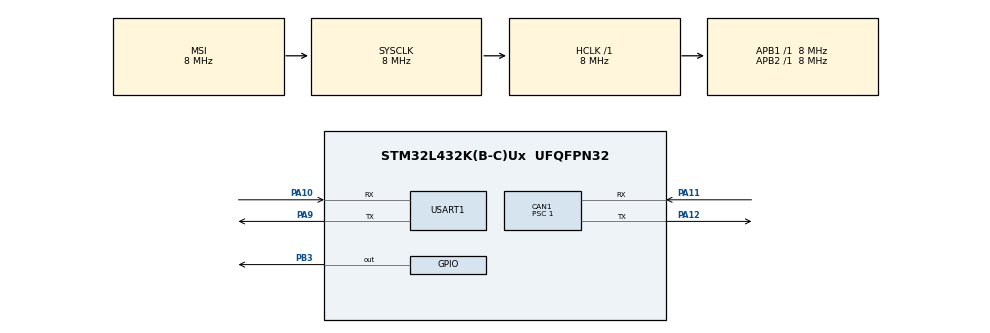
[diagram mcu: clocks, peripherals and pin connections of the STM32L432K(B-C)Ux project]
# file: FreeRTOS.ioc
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CAN1.BS1=CAN_BS1_5TQ
CAN1.BS2=CAN_BS2_2TQ
CAN1.CalculateBaudRate=1000000
CAN1.CalculateTimeBit=1000
CAN1.CalculateTimeQuantum=125.0
CAN1.Prescaler=1
FREERTOS.Tasks01=defaultTask,0,128,canopen_task,Default,NULL,Dynamic,NULL,NULL;myTask02,0,128,blink_task,Default,NULL,Dynamic,NULL,NULL
FREERTOS.configUSE_NEWLIB_REENTRANT=1
Mcu.Family=STM32L4
Mcu.Name=STM32L432K(B-C)Ux
Mcu.Package=UFQFPN32
NVIC.CAN1_RX0_IRQn=true\:5\:0\:false\:false\:true\:true\:true\:true\:true
NVIC.CAN1_RX1_IRQn=true\:5\:0\:false\:false\:true\:true\:true\:true\:true
NVIC.CAN1_TX_IRQn=true\:5\:0\:false\:false\:true\:true\:true\:true\:true
NVIC.PriorityGroup=NVIC_PRIORITYGROUP_4
NVIC.TIM1_UP_TIM16_IRQn=true\:15\:0\:false\:false\:true\:false\:false\:true\:true
NVIC.TIM7_IRQn=true\:5\:0\:false\:false\:true\:true\:true\:true\:true
NVIC.TimeBase=TIM1_UP_TIM16_IRQn
NVIC.TimeBaseIP=TIM1
NVIC.USART1_IRQn=true\:5\:0\:false\:false\:true\:true\:true\:true\:true
PA10.Mode=Asynchronous
PA10.Signal=USART1_RX
PA11.Mode=CAN_Activate
PA11.Signal=CAN1_RX
PA12.Mode=CAN_Activate
PA12.Signal=CAN1_TX
PA13\ (JTMS-SWDIO).Mode=Serial_Wire
PA13\ (JTMS-SWDIO).Signal=SYS_JTMS-SWDIO
PA14\ (JTCK-SWCLK).Mode=Serial_Wire
PA14\ (JTCK-SWCLK).Signal=SYS_JTCK-SWCLK
PA9.Mode=Asynchronous
PA9.Signal=USART1_TX
PB3\ (JTDO-TRACESWO).Signal=GPIO_Output
ProjectManager.HeapSize=0x200
ProjectManager.StackSize=0x400
ProjectManager.TargetToolchain=STM32CubeIDE
RCC.ADCFreq_Value=32000000
RCC.AHBFreq_Value=8000000
RCC.APB1Freq_Value=8000000
RCC.APB1TimFreq_Value=8000000
RCC.APB2Freq_Value=8000000
RCC.APB2TimFreq_Value=8000000
RCC.CortexFreq_Value=8000000
RCC.HCLKFreq_Value=8000000
RCC.HSE_VALUE=8000000
RCC.HSI48_VALUE=48000000
RCC.HSI_VALUE=16000000
RCC.LSE_VALUE=32768
RCC.MSIClockRange=RCC_MSIRANGE_7
RCC.MSI_VALUE=8000000
RCC.SYSCLKFreq_VALUE=8000000
RCC.USBFreq_Value=32000000
RCC.VCOOutputFreq_Value=64000000
TIM7.Period=1000
TIM7.Prescaler=63
USART1.VirtualMode-Asynchronous=VM_ASYNC
VP_FREERTOS_VS_CMSIS_V1.Mode=CMSIS_V1
VP_SYS_VS_tim1.Mode=TIM1
VP_TIM7_VS_ClockSourceINT.Mode=Enable_Timer
board=custom

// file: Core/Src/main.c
/* USER CODE BEGIN Header */
/**
  ******************************************************************************
  * @file           : main.c
  * @brief          : Main program body
  ******************************************************************************
  * @attention
  *
  * Copyright (c) 2024 STMicroelectronics.
  * All rights reserved.
  *
  * This software is licensed under terms that can be found in the LICENSE file
  * in the root directory of this software component.
  * If no LICENSE file comes with this software, it is provided AS-IS.
  *
  ******************************************************************************
  */
/* USER CODE END Header */
#include "main.h"
#include "cmsis_os.h"

/* USER CODE BEGIN Includes */
#include "CO_app_STM32.h"
/* USER CODE END Includes */

CAN_HandleTypeDef hcan1;

TIM_HandleTypeDef htim7;

UART_HandleTypeDef huart1;

osThreadId defaultTaskHandle;
osThreadId myTask02Handle;
/* USER CODE BEGIN PV */
uint8_t data[3] = "OK!";
/* USER CODE END PV */

void SystemClock_Config(void);
static void MX_GPIO_Init(void);
static void MX_CAN1_Init(void);
static void MX_TIM7_Init(void);
static void MX_USART1_UART_Init(void);
void canopen_task(void const * argument);
void blink_task(void const * argument);

int main(void)
{

  /* MCU Configuration--------------------------------------------------------*/

  /* Reset of all peripherals, Initializes the Flash interface and the Systick. */
  HAL_Init();

  /* Configure the system clock */
  SystemClock_Config();

  /* Initialize all configured peripherals */
  MX_GPIO_Init();
  MX_CAN1_Init();
  MX_TIM7_Init();
  MX_USART1_UART_Init();
  /* USER CODE BEGIN 2 */
  //HAL_UART_Transmit_IT(&huart1,data,3);
  /* USER CODE END 2 */

  /* Create the thread(s) */
  /* definition and creation of defaultTask */
  osThreadDef(defaultTask, canopen_task, osPriorityNormal, 0, 128);
  defaultTaskHandle = osThreadCreate(osThread(defaultTask), NULL);

  /* definition and creation of myTask02 */
  osThreadDef(myTask02, blink_task, osPriorityNormal, 0, 128);
  myTask02Handle = osThreadCreate(osThread(myTask02), NULL);

  /* Start scheduler */
  osKernelStart();

  /* We should never get here as control is now taken by the scheduler */
  /* Infinite loop */
  while (1)
  {

  }
}

void SystemClock_Config(void)
{
  RCC_OscInitTypeDef RCC_OscInitStruct = {0};
  RCC_ClkInitTypeDef RCC_ClkInitStruct = {0};

  /** Configure the main internal regulator output voltage
  */
  if (HAL_PWREx_ControlVoltageScaling(PWR_REGULATOR_VOLTAGE_SCALE1) != HAL_OK)
  {
    Error_Handler();
  }

  /** Initializes the RCC Oscillators according to the specified parameters
  * in the RCC_OscInitTypeDef structure.
  */
  RCC_OscInitStruct.OscillatorType = RCC_OSCILLATORTYPE_MSI;
  RCC_OscInitStruct.MSIState = RCC_MSI_ON;
  RCC_OscInitStruct.MSICalibrationValue = 0;
  RCC_OscInitStruct.MSIClockRange = RCC_MSIRANGE_7;
  RCC_OscInitStruct.PLL.PLLState = RCC_PLL_NONE;
  if (HAL_RCC_OscConfig(&RCC_OscInitStruct) != HAL_OK)
  {
    Error_Handler();
  }

  /** Initializes the CPU, AHB and APB buses clocks
  */
  RCC_ClkInitStruct.ClockType = RCC_CLOCKTYPE_HCLK|RCC_CLOCKTYPE_SYSCLK
                              |RCC_CLOCKTYPE_PCLK1|RCC_CLOCKTYPE_PCLK2;
  RCC_ClkInitStruct.SYSCLKSource = RCC_SYSCLKSOURCE_MSI;
  RCC_ClkInitStruct.AHBCLKDivider = RCC_SYSCLK_DIV1;
  RCC_ClkInitStruct.APB1CLKDivider = RCC_HCLK_DIV1;
  RCC_ClkInitStruct.APB2CLKDivider = RCC_HCLK_DIV1;

  if (HAL_RCC_ClockConfig(&RCC_ClkInitStruct, FLASH_LATENCY_0) != HAL_OK)
  {
    Error_Handler();
  }
}

static void MX_CAN1_Init(void)
{

  hcan1.Instance = CAN1;
  hcan1.Init.Prescaler = 1;
  hcan1.Init.Mode = CAN_MODE_NORMAL;
  hcan1.Init.SyncJumpWidth = CAN_SJW_1TQ;
  hcan1.Init.TimeSeg1 = CAN_BS1_5TQ;
  hcan1.Init.TimeSeg2 = CAN_BS2_2TQ;
  hcan1.Init.TimeTriggeredMode = DISABLE;
  hcan1.Init.AutoBusOff = DISABLE;
  hcan1.Init.AutoWakeUp = DISABLE;
  hcan1.Init.AutoRetransmission = DISABLE;
  hcan1.Init.ReceiveFifoLocked = DISABLE;
  hcan1.Init.TransmitFifoPriority = DISABLE;
  if (HAL_CAN_Init(&hcan1) != HAL_OK)
  {
    Error_Handler();
  }

}

static void MX_TIM7_Init(void)
{

  TIM_MasterConfigTypeDef sMasterConfig = {0};

  htim7.Instance = TIM7;
  htim7.Init.Prescaler = 63;
  htim7.Init.CounterMode = TIM_COUNTERMODE_UP;
  htim7.Init.Period = 1000;
  htim7.Init.AutoReloadPreload = TIM_AUTORELOAD_PRELOAD_DISABLE;
  if (HAL_TIM_Base_Init(&htim7) != HAL_OK)
  {
    Error_Handler();
  }
  sMasterConfig.MasterOutputTrigger = TIM_TRGO_RESET;
  sMasterConfig.MasterSlaveMode = TIM_MASTERSLAVEMODE_DISABLE;
  if (HAL_TIMEx_MasterConfigSynchronization(&htim7, &sMasterConfig) != HAL_OK)
  {
    Error_Handler();
  }

}

static void MX_USART1_UART_Init(void)
{

  huart1.Instance = USART1;
  huart1.Init.BaudRate = 115200;
  huart1.Init.WordLength = UART_WORDLENGTH_8B;
  huart1.Init.StopBits = UART_STOPBITS_1;
  huart1.Init.Parity = UART_PARITY_NONE;
  huart1.Init.Mode = UART_MODE_TX_RX;
  huart1.Init.HwFlowCtl = UART_HWCONTROL_NONE;
  huart1.Init.OverSampling = UART_OVERSAMPLING_16;
  huart1.Init.OneBitSampling = UART_ONE_BIT_SAMPLE_DISABLE;
  huart1.AdvancedInit.AdvFeatureInit = UART_ADVFEATURE_NO_INIT;
  if (HAL_UART_Init(&huart1) != HAL_OK)
  {
    Error_Handler();
  }

}

static void MX_GPIO_Init(void)
{
  GPIO_InitTypeDef GPIO_InitStruct = {0};

  /* GPIO Ports Clock Enable */
  __HAL_RCC_GPIOA_CLK_ENABLE();
  __HAL_RCC_GPIOB_CLK_ENABLE();

  /*Configure GPIO pin Output Level */
  HAL_GPIO_WritePin(GPIOB, GPIO_PIN_3, GPIO_PIN_RESET);

  /*Configure GPIO pin : PB3 */
  GPIO_InitStruct.Pin = GPIO_PIN_3;
  GPIO_InitStruct.Mode = GPIO_MODE_OUTPUT_PP;
  GPIO_InitStruct.Pull = GPIO_NOPULL;
  GPIO_InitStruct.Speed = GPIO_SPEED_FREQ_LOW;
  HAL_GPIO_Init(GPIOB, &GPIO_InitStruct);

}

void canopen_task(void const * argument)
{
  /* USER CODE BEGIN 5 */
  //static portTickType xLastWakeTime;
  //const portTickType xFrequency = pdMS_TO_TICKS(500);
  //xLastWakeTime = xTaskGetTickCount();
  CANopenNodeSTM32 canOpenNodeSTM32;
  canOpenNodeSTM32.CANHandle = &hcan1;
  canOpenNodeSTM32.HWInitFunction = MX_CAN1_Init;
  canOpenNodeSTM32.timerHandle = &htim7;
  canOpenNodeSTM32.desiredNodeID = 21;
  canOpenNodeSTM32.baudrate = 1000;
  canopen_app_init(&canOpenNodeSTM32);
  HAL_UART_Transmit_IT(&huart1,data,3);
  /* Infinite loop */
  for(;;)
  {
	//Reflect CANopenStatus on LEDs
    //HAL_GPIO_WritePin(GPIOB, GPIO_PIN_3, !canOpenNodeSTM32.outStatusLEDGreen);
    canopen_app_process();
    // Sleep for 1ms, you can decrease it if required, in the canopen_app_process we will double check to make sure 1ms passed
    //vTaskDelayUntil(xLastWakeTime,xFrequency);
    //vTaskDelay(pdMS_TO_TICKS(1));
    osDelay(1);
  }
  /* USER CODE END 5 */
}

void blink_task(void const * argument)
{
  /* USER CODE BEGIN blink_task */
  /* Infinite loop */
  for(;;)
  {
	HAL_GPIO_TogglePin(GPIOB,GPIO_PIN_3);
    osDelay(1);
	//vTaskDelay(pdMS_TO_TICKS(1));
  }
  /* USER CODE END blink_task */
}

void HAL_TIM_PeriodElapsedCallback(TIM_HandleTypeDef *htim)
{
  if (htim->Instance == TIM1) {
    HAL_IncTick();
  }
  /* USER CODE BEGIN Callback 1 */
  // Handle CANOpen app interrupts
  if (htim == canopenNodeSTM32->timerHandle)
  {
      canopen_app_interrupt();
  }
  /* USER CODE END Callback 1 */
}

void Error_Handler(void)
{
  __disable_irq();
  while (1)
  {
  }
}
